# CH572SFR register map
Vendor: WCH Ltd.; Series: CH572; File version: 1.1
CPU: RISC-V r0p0, little endian, no MPU, no FPU, 2 interrupt priority bits
Registers are 32-bit, read-write, reset 0x0 unless marked. A register's access mark holds for its fields unless they carry their own. Offsets are from the block's base; [hi:lo] are bit positions; lines under a group give offsets from that group; {n}, {i} and the like mark numbered series.

## PWMx
Base 0x40005000
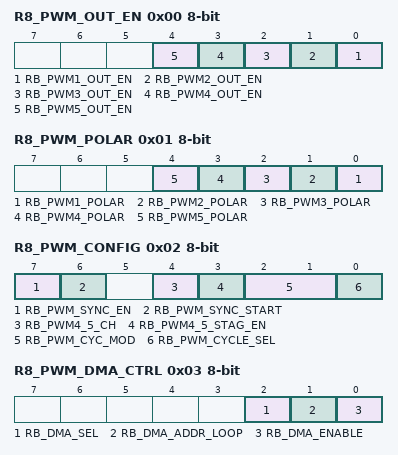
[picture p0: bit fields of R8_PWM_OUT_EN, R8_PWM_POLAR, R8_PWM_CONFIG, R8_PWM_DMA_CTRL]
0x00 R8_PWM_OUT_EN 8-bit — RW, PWM output enable control
  [n-1] RB_PWM{n}_OUT_EN (n=1..5) — RW, PWM{n} output enable
0x01 R8_PWM_POLAR 8-bit — RW, PWM output polarity control
  [n-1] RB_PWM{n}_POLAR (n=1..5) — RW, PWM{n} output polarity: 0=default low and high action, 1=default high and low action
0x02 R8_PWM_CONFIG 8-bit reset not defined — RW, PWM configuration
  [7] RB_PWM_SYNC_EN — RW, Synchronization enablement allows
  [6] RB_PWM_SYNC_START — RW, Sync Start
  [4] RB_PWM4_5_CH — RW, PWM4/5 channel output status
  [3] RB_PWM4_5_STAG_EN — RW, PWM4/5 stagger output enable: 0=independent output, 1=stagger output
  [2:1] RB_PWM_CYC_MOD — RW, PWM data width mode: 00=8 bits data, 01=7 bits data, 10=6 bits data, 11=5 bits data
  [0] RB_PWM_CYCLE_SEL — RW, PWM cycle selection: 0=256;128;64;32 clocks, 1=255;127;63;31 clocks
0x03 R8_PWM_DMA_CTRL 8-bit — RW, PWMx DMA control register
  [2] RB_DMA_SEL — RW, DMA output channel selection when RB_PWM_SYNC_EN=0
  [1] RB_DMA_ADDR_LOOP — RW, DMA Loop Output Enable
  [0] RB_DMA_ENABLE — RW, DMA enabled (only valid when the data width is 16)
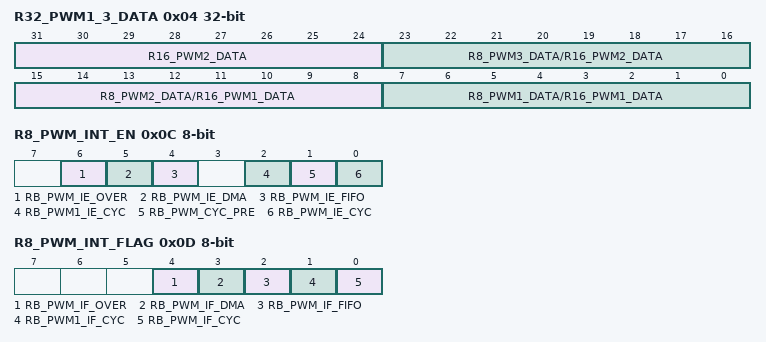
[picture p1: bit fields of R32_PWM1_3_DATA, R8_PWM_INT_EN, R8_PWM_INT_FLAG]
0x04 R32_PWM1_3_DATA reset not defined — RW, PWM data retention register group 1
  [31:24] R16_PWM2_DATA — RW, PWM2 data holding(16bits wide)
  [23:16] R8_PWM3_DATA/R16_PWM2_DATA — RW, PWM3 data holding or PWM2 data holding(16bits wide)
  [15:8] R8_PWM2_DATA/R16_PWM1_DATA — RW, PWM2 data holding or PWM1 data holding(16bits wide)
  [7:0] R8_PWM1_DATA/R16_PWM1_DATA — RW, PWM1 data holding or PWM1 data holding(16bits wide)
0x08 R16_PWM3_DATA 16-bit reset not defined — RW, PWM data retention register group 2
  [15:0] R16_PWM3_DATA — RW, PWM3 data retention register
0x0C R8_PWM_INT_EN 8-bit — RW, PWMx interrupt enable register
  [6] RB_PWM_IE_OVER — RW, FIFO read air interrupt enable bit
  [5] RB_PWM_IE_DMA — RW, DMA transfer end interrupt enable bit
  [4] RB_PWM_IE_FIFO — RW, FIFO data less than 4 interrupt enable bits
  [2] RB_PWM1_IE_CYC — RW, End of PWM4/5 cycle interrupt enable bit
  [1] RB_PWM_CYC_PRE — RW, Select the interrupt time point at the end of the PWM cycle
  [0] RB_PWM_IE_CYC — RW, End of PWM1/2/3 cycle interrupt enable bit
0x0D R8_PWM_INT_FLAG 8-bit — RW1, PWMx interrupt flag register
  [4] RB_PWM_IF_OVER — RW1, FIFO overflow interrupt flag bit
  [3] RB_PWM_IF_DMA — RW1, DMA transfer end interrupt flag bit
  [2] RB_PWM_IF_FIFO — RW1, FIFO data less than 4 interrupt flag bits
  [1] RB_PWM1_IF_CYC — RW1, PWM4/5 cycle end flag
  [0] RB_PWM_IF_CYC — RW1, PWM1/2/3 cycle end flag
0x10 R32_PWM4_5_DATA reset not defined — RW, PWM data retention register group 3
  [32:16] R16_PWM5_DATA — RW, PWM5 data holding(16bits wide)
  [15:8] R8_PWM5_DATA/R16_PWM4_DATA — RW, PWM5 data holding or PWM4 data holding(16bits wide)
  [7:0] R8_PWM4_DATA/R16_PWM4_DATA — RW, PWM4 data holding or PWM4 data holding(16bits wide)
0x14 R16_PWM_CYC_VALUE 16-bit reset not defined — RW, PWM1/2/3 cycles end register
  [15:0] R16_PWM_CYC_VALUE — RW, PWM1/2/3 clock cycle at 16 data widths
0x18 R16_PWM_CLOCK_DIV 16-bit — RW, PWM reference clock frequency division coefficient
  [15:0] R16_PWM_CLOCK_DIV — RW, DMA data buffer current address
0x1C R32_PWM_DMA_NOW reset not defined — RW, Current address of PWMx DMA buffer
0x20 R32_PWM_DMA_BEG reset not defined — RW, Starting address of PWMx DMA buffer
0x24 R32_PWM_DMA_END reset not defined — RW, End of PWMx DMA buffer

## Systick
Base 0xE000F000
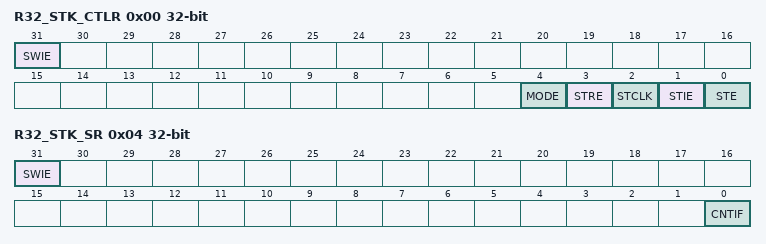
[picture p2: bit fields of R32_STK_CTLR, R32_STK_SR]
0x00 R32_STK_CTLR — Systick counter control register
  [31] SWIE — RW0,System soft interrupt enable
  [4] MODE — counter mode
  [3] STRE — System counter reload control
  [2] STCLK — System counter clock Source selection
  [1] STIE — Systick counter interrupt enable
  [0] STE — Systick counter enable
0x04 R32_STK_SR — Systick count status register
  [31] SWIE — RW, Enable software interrupt triggering
  [0] CNTIF — RW, CNTIF
0x08 R32_STK_CNTL — Systick counter low register
  [31:0] CNTL — RW, CNTL
0x10 R32_STK_CMPLR — Count reload low register
  [31:0] CNTH — RW,CNTH
0x10 R32_STK_CMPLR — Systick compare low register
  [31:0] CMPL — RW,CMPL
0x14 R32_STK_CMPHR — Systick compare high register
  [31:0] CMPH — RW, Set the reload counter value to the lower 32 bits
